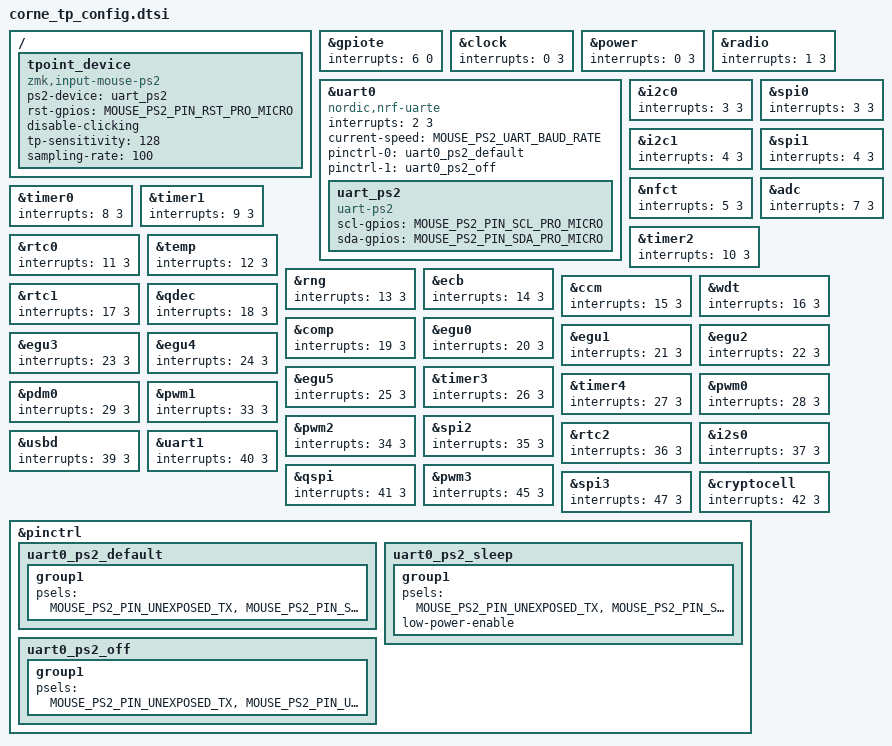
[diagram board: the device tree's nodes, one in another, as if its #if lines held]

/*
 * PS/2 Mouse / Trackpoint - User Configuration
 *
 * Enable PS/2 drivers on this side of the keyboard.
 * It MUST be the central half. If you connected your TP or mouse to the
 * left side, then move the following content to `your_keyboard_left.overlay`
 *
 * You also need to adjust `Kconfig.defconfig` and configure that this side
 * is the central side.
 *
 */

// Configure the SCL and SDA pins using the`&pro_micro` notation.
#define MOUSE_PS2_PIN_SCL_PRO_MICRO <&pro_micro 3 GPIO_ACTIVE_HIGH>
#define MOUSE_PS2_PIN_SDA_PRO_MICRO <&pro_micro 2 GPIO_ACTIVE_HIGH>


// Configure the Power-On-Reset pin
//
// Uncomment and configure this pin if you have an extra free pin and want the
// controller to perform the Power-On-Reset sequence, which many trackpoints
// require.
//
// You don't need this if you are not using a trackpoint or if you have a
// trackpoint reset circuit.
//
// It's ok to use a low-frequency pin for this.
// define MOUSE_PS2_PIN_RST_PRO_MICRO <&pro_micro 9 GPIO_ACTIVE_HIGH>


// Configure SDA pin using the pinctrl notation
//
// Now configure SDA pin using the pinctrl notation. Make sure to use the same
// pin as in the pro micro notation, but convert it to the pinctrl notation.
// We don't define the SCL pin, because UART uses a baud rate instead of a clock pin.
#define MOUSE_PS2_PIN_SDA_PINCTRL <NRF_PSEL(UART_RX, 0, 17)>

// Configure UART BAUD Rate
#define MOUSE_PS2_UART_BAUD_RATE <14400>

// Unexposed UART pins
// In UART two different pins are used for receiving and transmitting, but PS/2
// uses the same pin for both.
//
// The UART config still requires both pins to be configured. So we use one of
// the nrf52 pins that are not exposed on the nice!nano board.
#define MOUSE_PS2_PIN_UNEXPOSED_TX <NRF_PSEL(UART_TX, 0, 27)>
#define MOUSE_PS2_PIN_UNEXPOSED_RX <NRF_PSEL(UART_RX, 0, 28)>


// Adjust GPIO interrupt priority to the highest level.

// gpiote should have the highest interrupt priority (0)
&gpiote { interrupts = < 6 0 >; };

// All other priorities should be two levels lower than their defaults
// (which is usually 1 and should be demoted to 3)
&clock  { interrupts = < 0 3 >; };
&power  { interrupts = < 0 3 >; };
&radio  { interrupts = < 1 3 >; };
&uart0  { interrupts = < 2 3 >; };
&i2c0   { interrupts = < 3 3 >; };
&spi0   { interrupts = < 3 3 >; };
&i2c1   { interrupts = < 4 3 >; };
&spi1   { interrupts = < 4 3 >; };
&nfct   { interrupts = < 5 3 >; };
&adc    { interrupts = < 7 3 >; };
&timer0 { interrupts = < 8 3 >; };
&timer1 { interrupts = < 9 3 >; };
&timer2 { interrupts = < 10 3 >; };
&rtc0   { interrupts = < 11 3 >; };
&temp   { interrupts = < 12 3 >; };
&rng    { interrupts = < 13 3 >; };
&ecb    { interrupts = < 14 3 >; };
&ccm    { interrupts = < 15 3 >; };
&wdt    { interrupts = < 16 3 >; };
&rtc1   { interrupts = < 17 3 >; };
&qdec   { interrupts = < 18 3 >; };
&comp   { interrupts = < 19 3 >; };
&egu0   { interrupts = < 20 3 >; };
&egu1   { interrupts = < 21 3 >; };
&egu2   { interrupts = < 22 3 >; };
&egu3   { interrupts = < 23 3 >; };
&egu4   { interrupts = < 24 3 >; };
&egu5   { interrupts = < 25 3 >; };
&timer3 { interrupts = < 26 3 >; };
&timer4 { interrupts = < 27 3 >; };
&pwm0   { interrupts = < 28 3 >; };
&pdm0   { interrupts = < 29 3 >; };
&pwm1   { interrupts = < 33 3 >; };
&pwm2   { interrupts = < 34 3 >; };
&spi2   { interrupts = < 35 3 >; };
&rtc2   { interrupts = < 36 3 >; };
&i2s0   { interrupts = < 37 3 >; };
&usbd   { interrupts = < 39 3 >; };
&uart1  { interrupts = < 40 3 >; };
&qspi   { interrupts = < 41 3 >; };
&pwm3   { interrupts = < 45 3 >; };
&spi3   { interrupts = < 47 3 >; };
&cryptocell { interrupts = < 42 3 >; };

/*
 * PS/2 Mouse / Trackpoint - Device Definitions
 *
 * WARNING: Do not change anything beyond here unless you know what you are
 *          doing.
 */

&pinctrl {
	// This pinctrl state is used for receiving
	// For `UART_TX`, set an unused and unexposed pin
	// For `UART_RX`, set the PS/2 SDA pin number
	uart0_ps2_default: uart0_ps2_default {
		group1 {
			psels = MOUSE_PS2_PIN_UNEXPOSED_TX,
					MOUSE_PS2_PIN_SDA_PINCTRL;
		};
	};

	// Set this to the same pins as uart0_ps2_default
	uart0_ps2_sleep: uart0_ps2_sleep {
		group1 {
			psels = MOUSE_PS2_PIN_UNEXPOSED_TX,
					MOUSE_PS2_PIN_SDA_PINCTRL;
			low-power-enable;
		};
	};

	// The nrf52 UART controller is not compatible with the PS/2
	// transmission frame. So the PS/2 UART driver doesn't use UART for
	// transmissions and instead use GPIO bit-banging.
	//
	// When the driver switches to transmit mode, it frees up the SDA pin by
  // switching the UART controller to unexposed/unused pins.
	//
	// Then it configures the GPIO controller to use the SCL and SDA pins
	uart0_ps2_off: uart0_ps2_off {
		group1 {
			psels = MOUSE_PS2_PIN_UNEXPOSED_TX,
					MOUSE_PS2_PIN_UNEXPOSED_RX;
		};
	};
};

&uart0 {
    status = "disabled";
    compatible = "nordic,nrf-uarte";

    current-speed = MOUSE_PS2_UART_BAUD_RATE;
    pinctrl-0 = <&uart0_ps2_default>;
    pinctrl-1 = <&uart0_ps2_off>;

    pinctrl-names = "default", "sleep";

    uart_ps2: uart_ps2 {
        status="disabled";
        compatible = "uart-ps2";
        scl-gpios = MOUSE_PS2_PIN_SCL_PRO_MICRO;
        sda-gpios = MOUSE_PS2_PIN_SDA_PRO_MICRO;
    };
};

/ {
    tpoint_device: tpoint_device {
		status = "disabled";
        compatible = "zmk,input-mouse-ps2";
		ps2-device = <&uart_ps2>;
		#ifdef MOUSE_PS2_PIN_RST_PRO_MICRO
			rst-gpios = MOUSE_PS2_PIN_RST_PRO_MICRO;
		#endif
		};
};

&uart0 {
	status = "okay";
};
&uart_ps2 {
	status = "okay";
};
&tpoint_device {
	status = "okay";
	disable-clicking;
	tp-sensitivity = <128>;
	sampling-rate = <100>;
};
